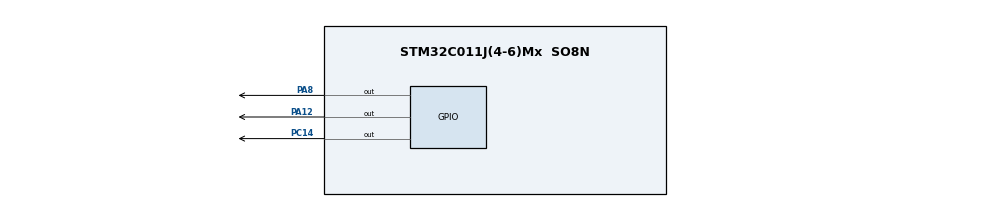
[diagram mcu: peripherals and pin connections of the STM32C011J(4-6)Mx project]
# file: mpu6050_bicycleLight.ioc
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Mcu.Family=STM32C0
Mcu.Name=STM32C011J(4-6)Mx
Mcu.Package=SO8N
PA12\ [PA10].Signal=GPIO_Output
PA13.Mode=Serial_Wire
PA13.Signal=DEBUG_SWDIO
PA14-BOOT0.Mode=Serial_Wire
PA14-BOOT0.Signal=DEBUG_SWCLK
PA8.GPIO_ModeDefaultOutputPP=GPIO_MODE_OUTPUT_OD
PA8.GPIO_PuPd=GPIO_PULLUP
PA8.Signal=GPIO_Output
PA8__PA11\ [PA9].StandardMode=true
PC14-OSCX_IN\ (PC14).Signal=GPIO_Output
PC14-OSCX_IN\ (PC14)__PB7.StandardMode=true
PC15-OSCX_OUT\ (PC15)__PA14-BOOT0__PB6.StandardMode=true
PF2-NRST__PA0__PA1__PA2.StandardMode=true
ProjectManager.HeapSize=0x200
ProjectManager.StackSize=0x400
ProjectManager.TargetToolchain=STM32CubeIDE
RCC.ADCFreq_Value=375000
RCC.AHBFreq_Value=375000
RCC.CortexFreq_Value=375000
RCC.EXTERNAL_CLOCK_VALUE=12288000
RCC.HCLKFreq_Value=375000
RCC.HSE_VALUE=8000000
RCC.HSISYSCLKDivider=RCC_HSI_DIV128
RCC.HSI_VALUE=48000000
RCC.LSE_VALUE=32768
RCC.SYSCLKFreq_VALUE=375000
board=custom

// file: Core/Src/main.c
/* USER CODE BEGIN Header */
/**
  ******************************************************************************
  * @file           : main.c
  * @brief          : Main program body
  ******************************************************************************
  * @attention
  *
  * Copyright (c) 2025 STMicroelectronics.
  * All rights reserved.
  *
  * This software is licensed under terms that can be found in the LICENSE file
  * in the root directory of this software component.
  * If no LICENSE file comes with this software, it is provided AS-IS.
  *
  ******************************************************************************
  */
/* USER CODE END Header */
#include "main.h"

/* USER CODE BEGIN Includes */
#include "debugLog.h"
#include "i2c_bitbang.h"
/* USER CODE END Includes */

/* USER CODE BEGIN PD */

#define MPU_ADDR   				0x68
#define MPU_REG_ACCEL_X        	0x3b
#define MPU_REG_ACCEL_Y        	0x3d
#define LightSwitch_Pin        	GPIO_PIN_14
#define LightSwitch_GPIO_Port  	GPIOC

/* USER CODE END PD */

/* USER CODE BEGIN PV */

int16_t xAccelArray[8];
int16_t yAccelArray[8];
uint8_t accelArray_pos=0;

/* USER CODE END PV */

void SystemClock_Config(void);
static void MX_GPIO_Init(void);

/* USER CODE BEGIN 0 */

int16_t getMedian(uint8_t arraySel){
	int16_t sum=0;
	for(uint8_t i=0;i<8;i++){
		if (arraySel == 0)
			sum += xAccelArray[i];
		else
			sum += yAccelArray[i];

	}
	return sum/8;
}

/* USER CODE END 0 */

int main(void)
{

  /* MCU Configuration--------------------------------------------------------*/

  /* Reset of all peripherals, Initializes the Flash interface and the Systick. */
  HAL_Init();

  /* Configure the system clock */
  SystemClock_Config();

  /* Initialize all configured peripherals */
  MX_GPIO_Init();

  /* Infinite loop */
  /* USER CODE BEGIN WHILE */
  uint16_t counter = 0, onCnt = 0, moveDetectCnt = 0;
  i2cWrite2bytes(MPU_ADDR, 0x6b, 0x00); // dummy write after power up
  i2cWrite2bytes(MPU_ADDR, 0x6b, 0x00); // PWR_MGMT_1 register - wake up
  i2cWrite2bytes(MPU_ADDR, 0x19, 0xff); // sample rate divider - highest divider
  i2cWrite2bytes(MPU_ADDR, 0x1c, 0x18); // Accel config register - scale to +/-16g

  //#define USE_DEBUG_LOG // debug log pin and light switch uses the same pin

  while (1)
  {
	  if (onCnt>0){
		  onCnt-=2;
	  }

	  i2cWrite2bytes(MPU_ADDR, 0x6b, 0x00); // PWR_MGMT_1 register - wake up
	  i2cWrite1byte(MPU_ADDR, MPU_REG_ACCEL_X);
	  int16_t accel_x = (int16_t)i2cRead2bytes(MPU_ADDR);
	  i2cWrite1byte(MPU_ADDR, MPU_REG_ACCEL_Y);
	  int16_t accel_y = (int16_t)i2cRead2bytes(MPU_ADDR);
	  i2cWrite2bytes(MPU_ADDR, 0x6b, 0x40); // PWR_MGMT_1 register - sleep

	  int16_t xDiff = getMedian(0) - accel_x;
	  int16_t yDiff = getMedian(1) - accel_y;

	  if (xDiff > 200 || xDiff < -200 || yDiff > 200 || yDiff < -200){ // movement detected
		  moveDetectCnt++;
		  if (moveDetectCnt>1)
			  onCnt=60; // set light on time
	  }
	  else
		  moveDetectCnt = 0;

	  // add to median-calc-array
	  xAccelArray[accelArray_pos] = accel_x;
	  yAccelArray[accelArray_pos] = accel_y;
	  accelArray_pos++;
	  if (accelArray_pos>7)
		  accelArray_pos=0;

	  // log
	  #ifdef USE_DEBUG_LOG
	  counter++;
	  sendDebugByte(counter>>8);
	  sendDebugByte(counter);
	  sendDebugByte(accel_x >> 8);
	  sendDebugByte(accel_x & 0xff);
	  sendDebugByte(accel_y >> 8);
	  sendDebugByte(accel_y & 0xff);
	  sendDebugByte(onCnt>>8);
	  sendDebugByte(onCnt);
	  #else
	  if (onCnt > 0){
		  HAL_GPIO_WritePin(LightSwitch_GPIO_Port, LightSwitch_Pin, GPIO_PIN_SET); // switch on
	  }
	  else{
		  HAL_GPIO_WritePin(LightSwitch_GPIO_Port, LightSwitch_Pin, GPIO_PIN_RESET); // switch off
	  }
	  #endif

	  HAL_Delay(2000);
    /* USER CODE END WHILE */

  }
}

void SystemClock_Config(void)
{
  RCC_OscInitTypeDef RCC_OscInitStruct = {0};
  RCC_ClkInitTypeDef RCC_ClkInitStruct = {0};

  __HAL_FLASH_SET_LATENCY(FLASH_LATENCY_0);

  /** Initializes the RCC Oscillators according to the specified parameters
  * in the RCC_OscInitTypeDef structure.
  */
  RCC_OscInitStruct.OscillatorType = RCC_OSCILLATORTYPE_HSI;
  RCC_OscInitStruct.HSIState = RCC_HSI_ON;
  RCC_OscInitStruct.HSIDiv = RCC_HSI_DIV128;
  RCC_OscInitStruct.HSICalibrationValue = RCC_HSICALIBRATION_DEFAULT;
  if (HAL_RCC_OscConfig(&RCC_OscInitStruct) != HAL_OK)
  {
    Error_Handler();
  }

  /** Initializes the CPU, AHB and APB buses clocks
  */
  RCC_ClkInitStruct.ClockType = RCC_CLOCKTYPE_HCLK|RCC_CLOCKTYPE_SYSCLK
                              |RCC_CLOCKTYPE_PCLK1;
  RCC_ClkInitStruct.SYSCLKSource = RCC_SYSCLKSOURCE_HSI;
  RCC_ClkInitStruct.SYSCLKDivider = RCC_SYSCLK_DIV1;
  RCC_ClkInitStruct.AHBCLKDivider = RCC_HCLK_DIV1;
  RCC_ClkInitStruct.APB1CLKDivider = RCC_APB1_DIV1;

  if (HAL_RCC_ClockConfig(&RCC_ClkInitStruct, FLASH_LATENCY_0) != HAL_OK)
  {
    Error_Handler();
  }
}

static void MX_GPIO_Init(void)
{
  GPIO_InitTypeDef GPIO_InitStruct = {0};

  /* GPIO Ports Clock Enable */
  __HAL_RCC_GPIOC_CLK_ENABLE();
  __HAL_RCC_GPIOA_CLK_ENABLE();

  /*Configure GPIO pin Output Level */
  HAL_GPIO_WritePin(GPIOC, GPIO_PIN_14, GPIO_PIN_RESET);

  /*Configure GPIO pin Output Level */
  HAL_GPIO_WritePin(GPIOA, GPIO_PIN_8|GPIO_PIN_12, GPIO_PIN_RESET);

  /*Configure GPIO pin : PC14 */
  GPIO_InitStruct.Pin = GPIO_PIN_14;
  GPIO_InitStruct.Mode = GPIO_MODE_OUTPUT_PP;
  GPIO_InitStruct.Pull = GPIO_NOPULL;
  GPIO_InitStruct.Speed = GPIO_SPEED_FREQ_LOW;
  HAL_GPIO_Init(GPIOC, &GPIO_InitStruct);

  /*Configure GPIO pin : PA8 */
  GPIO_InitStruct.Pin = GPIO_PIN_8;
  GPIO_InitStruct.Mode = GPIO_MODE_OUTPUT_OD;
  GPIO_InitStruct.Pull = GPIO_PULLUP;
  GPIO_InitStruct.Speed = GPIO_SPEED_FREQ_LOW;
  HAL_GPIO_Init(GPIOA, &GPIO_InitStruct);

  /*Configure GPIO pin : PA12 */
  GPIO_InitStruct.Pin = GPIO_PIN_12;
  GPIO_InitStruct.Mode = GPIO_MODE_OUTPUT_PP;
  GPIO_InitStruct.Pull = GPIO_NOPULL;
  GPIO_InitStruct.Speed = GPIO_SPEED_FREQ_LOW;
  HAL_GPIO_Init(GPIOA, &GPIO_InitStruct);

  /**/
  HAL_SYSCFG_SetPinBinding(HAL_BIND_SO8_PIN1_PC14|HAL_BIND_SO8_PIN5_PA8);

}

void Error_Handler(void)
{
  __disable_irq();
  while (1)
  {
  }
}
